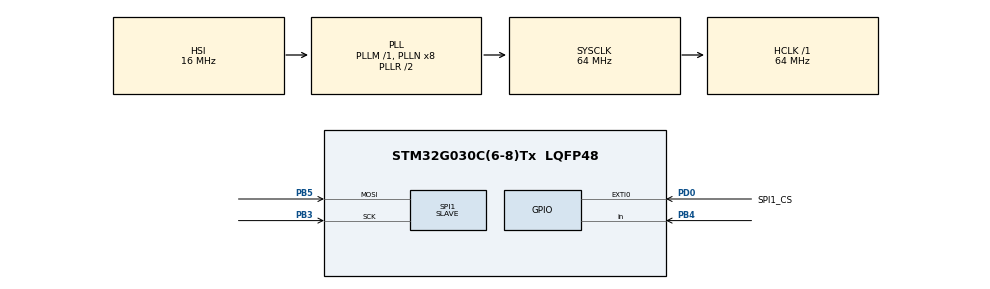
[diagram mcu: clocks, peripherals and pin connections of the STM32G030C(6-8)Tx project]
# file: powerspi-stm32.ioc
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Mcu.Family=STM32G0
Mcu.Name=STM32G030C(6-8)Tx
Mcu.Package=LQFP48
PB3.Mode=RX_Only_Simplex_Unidirect_Slave
PB3.Signal=SPI1_SCK
PB4.Signal=GPIO_Input
PB5.Mode=RX_Only_Simplex_Unidirect_Slave
PB5.Signal=SPI1_MOSI
PD0.GPIO_Label=SPI1_CS
PD0.GPIO_ModeDefaultEXTI=GPIO_MODE_IT_RISING_FALLING
PD0.Signal=GPXTI0
ProjectManager.HeapSize=0x200
ProjectManager.StackSize=0x400
ProjectManager.TargetToolchain=STM32CubeIDE
RCC.ADCFreq_Value=64000000
RCC.AHBFreq_Value=64000000
RCC.CortexFreq_Value=64000000
RCC.EXTERNAL_CLOCK_VALUE=12288000
RCC.HCLKFreq_Value=64000000
RCC.HSE_VALUE=8000000
RCC.HSI_VALUE=16000000
RCC.LSE_VALUE=32768
RCC.SYSCLKFreq_VALUE=64000000
RCC.SYSCLKSource=RCC_SYSCLKSOURCE_PLLCLK
RCC.VCOOutputFreq_Value=128000000
SPI1.Direction=SPI_DIRECTION_2LINES_RXONLY
SPI1.Mode=SPI_MODE_SLAVE
SPI1.VirtualType=VM_SLAVE
board=custom

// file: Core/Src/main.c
/* USER CODE BEGIN Header */
/**
  ******************************************************************************
  * @file           : main.c
  * @brief          : Main program body
  ******************************************************************************
  * @attention
  *
  * Copyright (c) 2023 STMicroelectronics.
  * All rights reserved.
  *
  * This software is licensed under terms that can be found in the LICENSE file
  * in the root directory of this software component.
  * If no LICENSE file comes with this software, it is provided AS-IS.
  *
  ******************************************************************************
  */
/* USER CODE END Header */
#include "main.h"
#include "spi.h"
#include "gpio.h"

/* USER CODE BEGIN Includes */
#include "powerspi.h"
/* USER CODE END Includes */

void SystemClock_Config(void);

/* USER CODE BEGIN 0 */

void HAL_GPIO_EXTI_Rising_Callback(uint16_t GPIO_Pin) {

}

void HAL_GPIO_EXTI_Falling_Callback(uint16_t GPIO_Pin) {

}

void HAL_SPI_TxCpltCallback(SPI_HandleTypeDef *hspi) {

}

void HAL_SPI_RxCpltCallback(SPI_HandleTypeDef *hspi) {

}

/* USER CODE END 0 */

int main(void)
{

  /* MCU Configuration--------------------------------------------------------*/

  /* Reset of all peripherals, Initializes the Flash interface and the Systick. */
  HAL_Init();

  /* Configure the system clock */
  SystemClock_Config();

  /* Initialize all configured peripherals */
  MX_GPIO_Init();
  MX_SPI1_Init();

  /* Infinite loop */
  while (1)
  {

  }
}

void SystemClock_Config(void)
{
  RCC_OscInitTypeDef RCC_OscInitStruct = {0};
  RCC_ClkInitTypeDef RCC_ClkInitStruct = {0};

  /** Configure the main internal regulator output voltage
  */
  HAL_PWREx_ControlVoltageScaling(PWR_REGULATOR_VOLTAGE_SCALE1);

  /** Initializes the RCC Oscillators according to the specified parameters
  * in the RCC_OscInitTypeDef structure.
  */
  RCC_OscInitStruct.OscillatorType = RCC_OSCILLATORTYPE_HSI;
  RCC_OscInitStruct.HSIState = RCC_HSI_ON;
  RCC_OscInitStruct.HSIDiv = RCC_HSI_DIV1;
  RCC_OscInitStruct.HSICalibrationValue = RCC_HSICALIBRATION_DEFAULT;
  RCC_OscInitStruct.PLL.PLLState = RCC_PLL_ON;
  RCC_OscInitStruct.PLL.PLLSource = RCC_PLLSOURCE_HSI;
  RCC_OscInitStruct.PLL.PLLM = RCC_PLLM_DIV1;
  RCC_OscInitStruct.PLL.PLLN = 8;
  RCC_OscInitStruct.PLL.PLLP = RCC_PLLP_DIV2;
  RCC_OscInitStruct.PLL.PLLR = RCC_PLLR_DIV2;
  if (HAL_RCC_OscConfig(&RCC_OscInitStruct) != HAL_OK)
  {
    Error_Handler();
  }

  /** Initializes the CPU, AHB and APB buses clocks
  */
  RCC_ClkInitStruct.ClockType = RCC_CLOCKTYPE_HCLK|RCC_CLOCKTYPE_SYSCLK
                              |RCC_CLOCKTYPE_PCLK1;
  RCC_ClkInitStruct.SYSCLKSource = RCC_SYSCLKSOURCE_PLLCLK;
  RCC_ClkInitStruct.AHBCLKDivider = RCC_SYSCLK_DIV1;
  RCC_ClkInitStruct.APB1CLKDivider = RCC_HCLK_DIV1;

  if (HAL_RCC_ClockConfig(&RCC_ClkInitStruct, FLASH_LATENCY_2) != HAL_OK)
  {
    Error_Handler();
  }
}

void Error_Handler(void)
{
  __disable_irq();
  while (1)
  {
  }
}
